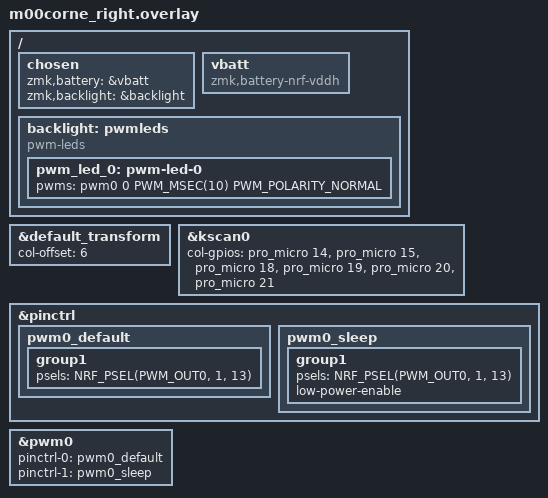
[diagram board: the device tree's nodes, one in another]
/*
 * Copyright (c) 2020 Pete Johanson
 *
 * SPDX-License-Identifier: MIT
 */

#include "m00corne.dtsi"

&default_transform {
	col-offset = <6>;
};

&kscan0 {
    col-gpios
        = <&pro_micro 14  GPIO_ACTIVE_HIGH>
        , <&pro_micro 15  GPIO_ACTIVE_HIGH>
        , <&pro_micro 18  GPIO_ACTIVE_HIGH>
        , <&pro_micro 19  GPIO_ACTIVE_HIGH>
        , <&pro_micro 20  GPIO_ACTIVE_HIGH>
        , <&pro_micro 21  GPIO_ACTIVE_HIGH>
        ;
};
/ {
    chosen {
      zmk,battery = &vbatt;
      zmk,backlight = &backlight;
    };

    vbatt: vbatt {
        compatible = "zmk,battery-nrf-vddh";
    };

    backlight: pwmleds {
        compatible = "pwm-leds";

        pwm_led_0: pwm-led-0 {
            pwms = <&pwm0 0 PWM_MSEC(10) PWM_POLARITY_NORMAL>;
        };
    };
};

&pinctrl {
    pwm0_default: pwm0_default {
        group1 {
            psels = <NRF_PSEL(PWM_OUT0, 1, 13)>;
        };
    };
    pwm0_sleep: pwm0_sleep {
        group1 {
            psels = <NRF_PSEL(PWM_OUT0, 1, 13)>;
            low-power-enable;
        };
    };
};

&pwm0 {
    status = "okay";
    pinctrl-0 = <&pwm0_default>;
    pinctrl-1 = <&pwm0_sleep>;
    pinctrl-names = "default", "sleep";
};
